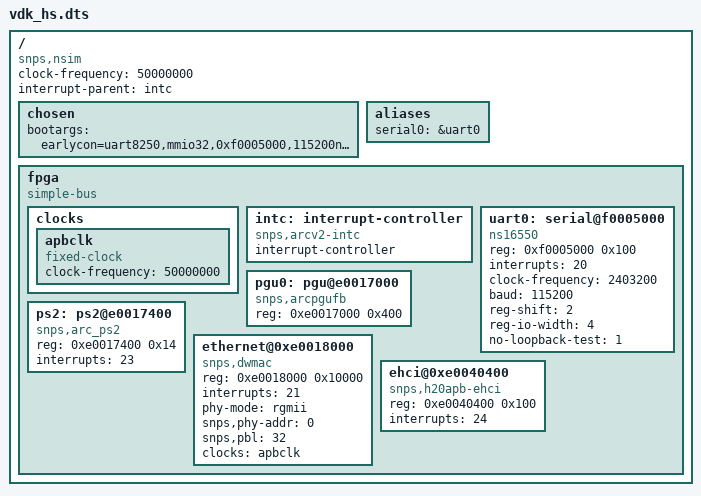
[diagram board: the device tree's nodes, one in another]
/*
 * Copyright (C) 2014 Synopsys, Inc. (www.synopsys.com)
 *
 * This program is free software; you can redistribute it and/or modify
 * it under the terms of the GNU General Public License version 2 as
 * published by the Free Software Foundation.
 */
/dts-v1/;

/include/ "skeleton.dtsi"

/ {
	compatible = "snps,nsim";
	clock-frequency = <50000000>;	/* 50 MHZ */
	#address-cells = <1>;
	#size-cells = <1>;
	interrupt-parent = <&intc>;

	chosen {
		bootargs = "earlycon=uart8250,mmio32,0xf0005000,115200n8 console=ttyS0,115200n8"  ;
	};

	aliases {
		serial0 = &uart0;
	};

	fpga {
		compatible = "simple-bus";
		#address-cells = <1>;
		#size-cells = <1>;

		/* child and parent address space 1:1 mapped */
		ranges;

		clocks {
			apbclk: apbclk {
				compatible = "fixed-clock";
				clock-frequency = <50000000>;
				#clock-cells = <0>;
			};
		};

		intc: interrupt-controller {
			compatible = "snps,arcv2-intc";
			interrupt-controller;
			#interrupt-cells = <1>;
		};

		uart0: serial@f0005000 {
			compatible = "ns16550";
			reg = <0xf0005000 0x100>;
			interrupts = <20>;
			clock-frequency = <2403200>;
			baud = <115200>;
			reg-shift = <2>;
			reg-io-width = <4>;
			no-loopback-test = <1>;
		};


                pgu0: pgu@e0017000 {
                        compatible = "snps,arcpgufb";
                        reg = <0xe0017000 0x400>;
                };

                ps2: ps2@e0017400 {
                        compatible = "snps,arc_ps2";
                        reg = <0xe0017400 0x14>;
                        interrupts = <23>;
                        interrupt-names = "arc_ps2_irq";
                };


                ethernet@0xe0018000 {
                        #interrupt-cells = <1>;
                        compatible = "snps,dwmac";
                        reg = < 0xe0018000 0x10000 >;
                        interrupts = < 21 >;
                        interrupt-names = "macirq";
                        phy-mode = "rgmii";
                        snps,phy-addr = < 0 >;
                        snps,pbl = < 32 >;
                        clocks = <&apbclk>;
                        clock-names = "stmmaceth";
                };

		ehci@0xe0040400 {
			compatible = "snps,h20apb-ehci";
			reg = < 0xe0040400 0x100 >;
			interrupts = <24>;
		};

	};
};
